# CEC1702 register map
Vendor: Microchip Technology; Series: CEC1702Q; File version: 0
CPU: CM4 r1p0, little endian, MPU, FPU, 3 interrupt priority bits, 155 interrupts
Registers are 32-bit, read-write, reset 0x0 unless marked. A register's access mark holds for its fields unless they carry their own. Offsets are from the block's base; [hi:lo] are bit positions; lines under a group give offsets from that group; {n}, {i} and the like mark numbered series.

## DMA_MAIN — DMA Main Registers
Base 0x40002400; register names take the prefix DMA_MAIN_
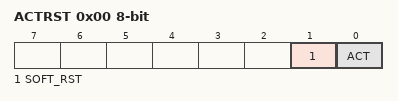
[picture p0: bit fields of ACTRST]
0x00 ACTRST 8-bit — Soft reset the entire module. Enable the blocks operation.
  [1] SOFT_RST — Soft reset the entire module. This bit is self-clearing.
  [0] ACT — Enable the blocks operation. (R/WS). 1=Enable block. Each individual channel must be enabled separately. 0=Disable all channels.
0x04 DATA_PKT ro — Debug register that has the data that is stored in the Data Packet. This data is read data from the currently active transfer source.

## ECIA — The interrupt generation logic is made of 16 groups of signals, each of which consist of a Status register, a Enable register and a Result register. The Status and Enable are latched registers. The Result register is a bit by bit AND function of the Source and Enable registers. All the bits of the Result register are OR'ed together and AND'ed with the corresponding bit in the Block. Select register to form the interrupt signal that is routed to the ARM interrupt controller.
Base 0x4000E000; register names take the prefix ECIA_
{0x0+0x14*i} GIRQ[{i}] (i=0..18) group
  0x00 SRC — Status R/W1C
  0x04 EN_SET — Write to set source enables
  0x08 RESULT ro — Read-only bitwise OR of Source and Enable
  0x0C EN_CLR — Write to clear source enables
0x200 BLK_EN_SET — Block Enable Set Register
  [30:0] VTOR_EN_SET — Each GIRQx bit can be individually enabled to assert an interrupt event. Reads always return the current value of the internal GIRQX_ENABLE bit. The state of the GIRQX_ENABLE bit is determined by the corresponding GIRQX_ENABLE_SET bit and the GIRQX_ENABLE_ CLEAR bit. (0=disabled, 1=enabled) (R/WS). 1=Interrupts in the GIRQx Source Register may be enabled. 0=No effect.
0x204 BLK_EN_CLR — Block Enable Clear Register.
  [30:0] VTOR_EN_CLR — Each GIRQx bit can be individually disabled to inhibit an interrupt event. Reads always return the current value of the internal GIRQX_ENABLE bit. The state of the GIRQX_ENABLE bit is determined by the corresponding GIRQX_ENABLE_SET bit and the GIRQX_ENABLE_ CLEAR bit. (0=disabled, 1=enabled) (R/WC). 1=All interrupts in the GIRQx Source Register are disabled. 0=No effect.
0x208 BLK_IRQ_VTOR ro — Block IRQ Vector Register
  [24:0] VTOR — Each bit in this field reports the status of the group GIRQ interrupt assertion to the NVIC. If the GIRQx interrupt is disabled as a group, by the Block Enable Clear Register, then the corresponding bit will be '0'b and no interrupt will be asserted.

## GCR — The Logical Device Configuration registers support motherboard designs in which the resources required by their components are known and assigned by the BIOS at POST.
Base 0x400FFF00; register names take the prefix GCR_
0x07 LDN 8-bit — A write to this register selects the current logical device. This allows access to the control and configuration registers for each logical device. Note: The Activate command operates only on the selected logical device.
0x20 DEV_ID 8-bit ro reset 0x31 — A read-only register which provides device identification.
0x21 DEV_REV 8-bit ro — A read-only register which provides device revision information.

## WDT — The function of the Watchdog Timer is to provide a mechanism to detect if the internal embedded controller has failed. When enabled, the Watchdog Timer (WDT) circuit will generate a WDT Event if the user program fails to reload the WDT within a specified length of time known as the WDT Interval.
Base 0x40000000; register names take the prefix WDT_
0x00 LOAD 16-bit reset 0xF — Writing this field reloads the Watch Dog Timer counter.
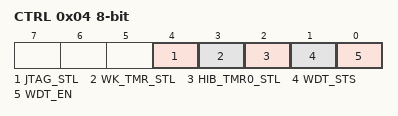
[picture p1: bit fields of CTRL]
0x04 CTRL 8-bit — WDT Control Register
  [4] JTAG_STL — This bit enables the WDT Stall function if JTAG or SWD debug functions are active. 1=The WDT is stalled while either JTAG or SWD is active. 0=The WDT is not affected by the JTAG debug interface.
  [3] WK_TMR_STL — This bit enables the WDT Stall function if the Week Timer is active. 1=The WDT is stalled while the Week Timer is active. 0=The WDT is not affected by the Week Timer.
  [2] HIB_TMR0_STL — This bit enables the WDT Stall function if the Hibernation Timer 0 is active. 1=The WDT is stalled while the Hibernation Timer 0 is active. 0=The WDT is not affected by Hibernation Timer 0.
  [1] WDT_STS — WDT_STS is set by hardware if the last reset of the device was caused by an underflow of the WDT. This bit must be cleared by the EC firmware writing a '1' to this bit. Writing a '0' to this bit has no effect.
  [0] WDT_EN — WDT Block enabled
0x08 KICK 8-bit wo — The WDT Kick Register is a strobe. Reads of this register return 0. Writes to this register cause the WDT to reload the WDT Load Register value and start decrementing when the WDT_ENABLE bit in the WDT Control Register is set to '1'. When the WDT_ENABLE bit in the WDT Control Register is cleared to '0', writes to the WDT Kick Register have no effect.
0x0C CNT 16-bit ro reset 0xFFFF — This read-only register provides the current WDT count.
